# LPC802 register map
Vendor: nxp.com; File version: 1.0
CPU: CM0PLUS r0p0, little endian, no MPU, no FPU, VTOR, 2 interrupt priority bits
Registers are 32-bit, read-write, reset 0x0 unless marked. A register's access mark holds for its fields unless they carry their own. Offsets are from the block's base; [hi:lo] are bit positions; {n}, {i} and the like mark numbered series; 'fields as' and 'values as' point back to an identical list.

## ACOMP — analog comparator
Base 0x40024000
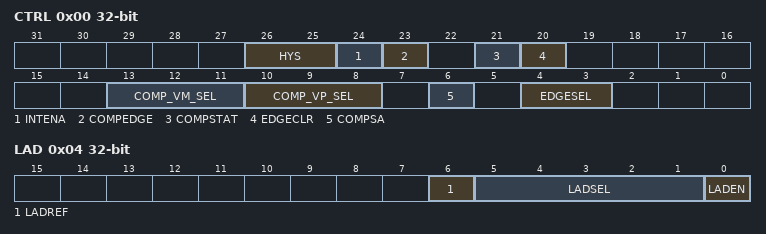
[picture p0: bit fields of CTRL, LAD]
0x00 CTRL (reset mask 0x6C03F58) — Comparator control register
  [26:25] HYS — Controls the hysteresis of the comparator. When the comparator is outputting a certain state, this is the difference between the selected signals, in the opposite direction from the state being output, that will switch the output.
    0=None (the output will switch as the voltages cross); 1=5 mv; 2=10 mv; 3=20 mv
  [24] INTENA — Must be set to generate interrupts.
  [23] COMPEDGE — Comparator edge-detect status.
  [21] COMPSTAT — Comparator status. This bit reflects the state of the comparator output.
  [20] EDGECLR — Interrupt clear bit. To clear the COMPEDGE bit and thus negate the interrupt request, toggle the EDGECLR bit by first writing a 1 and then a 0.
  [13:11] COMP_VM_SEL — Selects negative voltage input
    0=VOLTAGE_LADDER_OUTPUT; {v}=ACMP_I{v} (v=1..5); 6=BAND_GAP (Band gap. Internal reference voltage.); 7=DACOUT0 (DAC0 output)
  [10:8] COMP_VP_SEL — Selects positive voltage input
    values as COMP_VM_SEL
  [6] COMPSA — Comparator output control
    0=Comparator output is used directly; 1=Comparator output is synchronized to the bus clock for output to other modules
  [4:3] EDGESEL — This field controls which edges on the comparator output set the COMPEDGE bit (bit 23 below):
    0=FALLING_EDGES; 1=RISING_EDGES; 2=BOTH_EDGES0; 3=BOTH_EDGES1
0x04 LAD — Voltage ladder register
  [6] LADREF — Selects the reference voltage Vref for the voltage ladder.
    0=Supply pin VDD; 1=VDDCMP pin
  [5:1] LADSEL — Voltage ladder value. The reference voltage Vref depends on the LADREF bit below. 00000 = VSS 00001 = 1 x Vref/31 00010 = 2 x Vref/31 ... 11111 = Vref
  [0] LADEN — Voltage ladder enable

## IOCON — LPC802 I/O pin configuration (IOCON)
Base 0x40044000
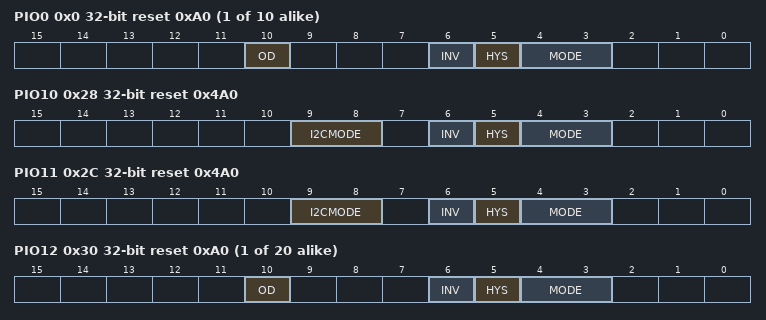
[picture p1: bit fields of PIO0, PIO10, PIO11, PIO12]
{0x0+4i} PIO{i} reset 0xA0 (reset mask 0xFFFFFFE0) (i=0..9) — Digital I/O control for port 0 pins PIO{i}
  [10] OD — Open-drain mode.
    0=DISABLE; 1=ENABLED (Open-drain mode enabled. Remark: This is not a true open-drain mode.)
  [6] INV — Invert input
    0=NOT_INVERTED (Input not inverted (HIGH on pin reads as 1; LOW on pin reads as 0).); 1=INVERTED (Input inverted (HIGH on pin reads as 0, LOW on pin reads as 1).)
  [5] HYS — Hysteresis.
    0=DISABLE; 1=ENABLE
  [4:3] MODE — Selects function mode (on-chip pull-up/pull-down resistor control).
    0=INACTIVE (Inactive. Inactive (no pull-down/pull-up resistor enabled).); 1=PULL_DOWN (Pull-down. Pull-down resistor enabled.); 2=PULL_UP (Pull-up. Pull-up resistor enabled.); 3=REPEATER (Repeater. Repeater mode.)
0x28 PIO10 reset 0x4A0 (reset mask 0xFFFFFFE0) — Digital I/O control for port 0 pins PIO10
  [9:8] I2CMODE — Selects I2C mode.
    0=STANDARAD_I2C (Standard mode/ Fast-mode I2C.); 1=Standard GPIO functionality. Requires external pull-up for GPIO output function.; 2=FAST_PLUS_I2C (Fast-mode Plus I2C)
  [6] INV — Invert input
    values as PIO0.INV
  [5] HYS — Hysteresis.
    0=DISABLE; 1=ENABLE
  [4:3] MODE — Selects function mode (on-chip pull-up/pull-down resistor control).
    values as PIO0.MODE
0x2C PIO11 reset 0x4A0 (reset mask 0xFFFFFFE0) — Digital I/O control for port 0 pins PIO11
  fields as PIO10
{0x0+4i} PIO{i} reset 0xA0 (reset mask 0xFFFFFFE0) (i=12..31) — Digital I/O control for port 0 pins PIO{i}
  fields as PIO0
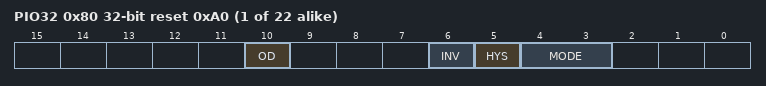
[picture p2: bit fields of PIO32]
{0x0+4i} PIO{i} reset 0xA0 (reset mask 0xFFFFFFE0) (i=32..53) — Digital I/O control for port 1 pins PIO{i}
  fields as PIO0

## CRC — CRC engine
Base 0x50000000
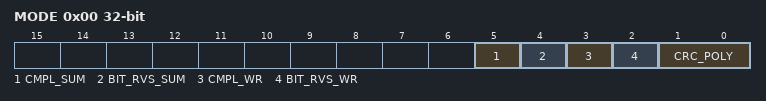
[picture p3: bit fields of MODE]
0x00 MODE — CRC mode register
  [5] CMPL_SUM — CRC sum complement: 1 = 1's complement for CRC_SUM 0 = No 1's complement for CRC_SUM
  [4] BIT_RVS_SUM — CRC sum bit order: 1 = Bit order reverse for CRC_SUM 0 = No bit order reverse for CRC_SUM
  [3] CMPL_WR — Data complement: 1 = 1's complement for CRC_WR_DATA 0 = No 1's complement for CRC_WR_DATA
  [2] BIT_RVS_WR — Data bit order: 1 = Bit order reverse for CRC_WR_DATA (per byte) 0 = No bit order reverse for CRC_WR_DATA (per byte)
  [1:0] CRC_POLY — CRC polynomial: 1X = CRC-32 polynomial 01 = CRC-16 polynomial 00 = CRC-CCITT polynomial
0x04 SEED reset 0xFFFF — CRC seed register
  [31:0] CRC_SEED — A write access to this register will load CRC seed value to CRC_SUM register with selected bit order and 1's complement pre-processes. A write access to this register will overrule the CRC calculation in progresses.
0x08 SUM ro reset 0xFFFF (SUM_WR_DATA view) — CRC checksum register
  [31:0] CRC_SUM — The most recent CRC sum can be read through this register with selected bit order and 1's complement post-processes.
0x08 WR_DATA wo reset not defined (SUM_WR_DATA view) — CRC data register
  [31:0] CRC_WR_DATA — Data written to this register will be taken to perform CRC calculation with selected bit order and 1's complement pre-process. Any write size 8, 16 or 32-bit are allowed and accept back-to-back transactions.

## Notices in the file
The Clear BSD License
Copyright 2016-2018 NXP
All rights reserved.
Redistribution and use in source and binary forms, with or without
modification, are permitted (subject to the limitations in the
disclaimer below) provided that the following conditions are met:
Redistributions of source code must retain the above copyright
notice, this list of conditions and the following disclaimer.
Redistributions in binary form must reproduce the above copyright
notice, this list of conditions and the following disclaimer in the
documentation and/or other materials provided with the distribution.
Neither the name of the copyright holder nor the names of its
contributors may be used to endorse or promote products derived from
this software without specific prior written permission.
NO EXPRESS OR IMPLIED LICENSES TO ANY PARTY'S PATENT RIGHTS ARE
GRANTED BY THIS LICENSE. THIS SOFTWARE IS PROVIDED BY THE COPYRIGHT
HOLDERS AND CONTRIBUTORS "AS IS" AND ANY EXPRESS OR IMPLIED
WARRANTIES, INCLUDING, BUT NOT LIMITED TO, THE IMPLIED WARRANTIES OF
MERCHANTABILITY AND FITNESS FOR A PARTICULAR PURPOSE ARE
DISCLAIMED. IN NO EVENT SHALL THE COPYRIGHT HOLDER OR CONTRIBUTORS BE
LIABLE FOR ANY DIRECT, INDIRECT, INCIDENTAL, SPECIAL, EXEMPLARY, OR
CONSEQUENTIAL DAMAGES (INCLUDING, BUT NOT LIMITED TO, PROCUREMENT OF
SUBSTITUTE GOODS OR SERVICES; LOSS OF USE, DATA, OR PROFITS; OR
BUSINESS INTERRUPTION) HOWEVER CAUSED AND ON ANY THEORY OF LIABILITY,
WHETHER IN CONTRACT, STRICT LIABILITY, OR TORT (INCLUDING NEGLIGENCE
OR OTHERWISE) ARISING IN ANY WAY OUT OF THE USE OF THIS SOFTWARE, EVEN
IF ADVISED OF THE POSSIBILITY OF SUCH DAMAGE.
